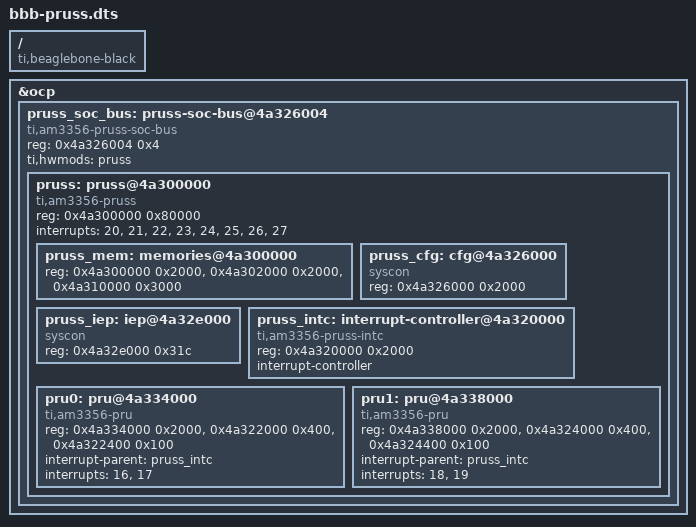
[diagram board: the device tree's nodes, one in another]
/*
 * BeagleBone Black capemgr overlay: aktiviert PRUSS + PRU0/PRU1 als
 * remoteproc-Cores (ti,am3356-pruss / ti,am3356-pru). Adaptiert von
 * beagleboard/bb.org-overlays (AM335X-PRU-RPROC-4-19-TI-00A0.dts,
 * SPDX-License-Identifier: GPL-2.0-only, Copyright (C) 2015 Texas
 * Instruments Incorporated) auf das fragment@N-Overlay-Schema dieses
 * Projekts (siehe bbb-bme280.dts). Register-Layout/Interrupt-Zuordnung
 * unverändert aus der Referenz übernommen. firmware-name bewusst
 * weggelassen — project/c/src/pru.c setzt die Firmware explizit über
 * remoteproc-sysfs vor dem Start (kein Auto-Boot beim Kernel-Start).
 * Siehe Issue #252.
 */
/dts-v1/;
/plugin/;

/ {
	compatible = "ti,beaglebone-black";

	fragment@0 {
		target = <&ocp>;
		__overlay__ {
			#address-cells = <1>;
			#size-cells = <1>;

			pruss_soc_bus: pruss-soc-bus@4a326004 {
				compatible = "ti,am3356-pruss-soc-bus";
				reg = <0x4a326004 0x4>;
				ti,hwmods = "pruss";
				#address-cells = <1>;
				#size-cells = <1>;
				ranges;
				status = "okay";

				pruss: pruss@4a300000 {
					compatible = "ti,am3356-pruss";
					reg = <0x4a300000 0x80000>;
					interrupts = <20>, <21>, <22>, <23>, <24>, <25>, <26>, <27>;
					interrupt-names = "host2", "host3", "host4",
							   "host5", "host6", "host7",
							   "host8", "host9";
					#address-cells = <1>;
					#size-cells = <1>;
					ranges;
					status = "okay";

					pruss_mem: memories@4a300000 {
						reg = <0x4a300000 0x2000>,
						      <0x4a302000 0x2000>,
						      <0x4a310000 0x3000>;
						reg-names = "dram0", "dram1", "shrdram2";
					};

					pruss_cfg: cfg@4a326000 {
						compatible = "syscon";
						reg = <0x4a326000 0x2000>;
					};

					pruss_iep: iep@4a32e000 {
						compatible = "syscon";
						reg = <0x4a32e000 0x31c>;
					};

					pruss_intc: interrupt-controller@4a320000 {
						compatible = "ti,am3356-pruss-intc";
						reg = <0x4a320000 0x2000>;
						interrupt-controller;
						#interrupt-cells = <1>;
					};

					pru0: pru@4a334000 {
						compatible = "ti,am3356-pru";
						reg = <0x4a334000 0x2000>,
						      <0x4a322000 0x400>,
						      <0x4a322400 0x100>;
						reg-names = "iram", "control", "debug";
						interrupt-parent = <&pruss_intc>;
						interrupts = <16>, <17>;
						interrupt-names = "vring", "kick";
					};

					pru1: pru@4a338000 {
						compatible = "ti,am3356-pru";
						reg = <0x4a338000 0x2000>,
						      <0x4a324000 0x400>,
						      <0x4a324400 0x100>;
						reg-names = "iram", "control", "debug";
						interrupt-parent = <&pruss_intc>;
						interrupts = <18>, <19>;
						interrupt-names = "vring", "kick";
					};
				};
			};
		};
	};
};
